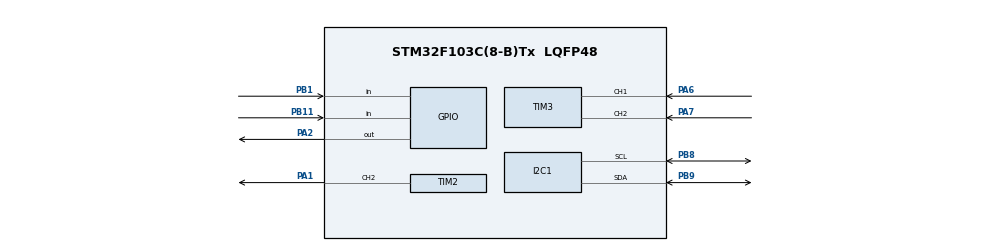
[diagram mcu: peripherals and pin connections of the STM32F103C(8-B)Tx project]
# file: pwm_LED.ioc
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Mcu.Family=STM32F1
Mcu.Name=STM32F103C(8-B)Tx
Mcu.Package=LQFP48
NVIC.PriorityGroup=NVIC_PRIORITYGROUP_4
PA1.Signal=S_TIM2_CH2
PA13.Mode=Serial_Wire
PA13.Signal=SYS_JTMS-SWDIO
PA14.Mode=Serial_Wire
PA14.Signal=SYS_JTCK-SWCLK
PA2.Signal=GPIO_Output
PA6.Signal=S_TIM3_CH1
PA7.Signal=S_TIM3_CH2
PB1.GPIO_PuPd=GPIO_PULLUP
PB1.Signal=GPIO_Input
PB11.GPIO_PuPd=GPIO_PULLUP
PB11.Signal=GPIO_Input
PB8.Mode=I2C
PB8.Signal=I2C1_SCL
PB9.Mode=I2C
PB9.Signal=I2C1_SDA
ProjectManager.HeapSize=0x200
ProjectManager.StackSize=0x400
ProjectManager.TargetToolchain=CMake
RCC.APB1Freq_Value=8000000
RCC.APB2Freq_Value=8000000
SH.S_TIM2_CH2.0=TIM2_CH2,PWM Generation2 CH2
SH.S_TIM3_CH1.0=TIM3_CH1,Encoder_Interface
SH.S_TIM3_CH2.0=TIM3_CH2,Encoder_Interface
TIM2.Channel-PWM\ Generation2\ CH2=TIM_CHANNEL_2
board=custom

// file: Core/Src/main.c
/* USER CODE BEGIN Header */
/**
  ******************************************************************************
  * @file           : main.c
  * @brief          : Main program body
  ******************************************************************************
  * @attention
  *
  * Copyright (c) 2026 STMicroelectronics.
  * All rights reserved.
  *
  * This software is licensed under terms that can be found in the LICENSE file
  * in the root directory of this software component.
  * If no LICENSE file comes with this software, it is provided AS-IS.
  *
  ******************************************************************************
  */
/* USER CODE END Header */
#include "main.h"

I2C_HandleTypeDef hi2c1;

TIM_HandleTypeDef htim2;
TIM_HandleTypeDef htim3;

/* USER CODE BEGIN PV */
static uint16_t s_bright   = 500u;   /* 上电半亮 */
static uint16_t s_enc_last = 0u;
static int32_t s_enc_acc = 0;   /* 攒够一格才动作 */

/* USER CODE END PV */

void SystemClock_Config(void);
static void MX_GPIO_Init(void);
static void MX_I2C1_Init(void);
static void MX_TIM2_Init(void);
static void MX_TIM3_Init(void);

int main(void)
{

  /* MCU Configuration--------------------------------------------------------*/

  /* Reset of all peripherals, Initializes the Flash interface and the Systick. */
  HAL_Init();

  /* Configure the system clock */
  SystemClock_Config();

  /* Initialize all configured peripherals */
  MX_GPIO_Init();
  MX_I2C1_Init();
  MX_TIM2_Init();
  MX_TIM3_Init();
  /* USER CODE BEGIN 2 */
/* 启动 TIM3 硬件编码器接口（A = PA6, B = PA7, C 接 GND）*/
  HAL_TIM_Encoder_Start(&htim3, TIM_CHANNEL_ALL);
  s_enc_last = (uint16_t)__HAL_TIM_GET_COUNTER(&htim3);

  /* 启动 TIM2_CH2 的 PWM 输出（LED = PA1）*/
  HAL_TIM_PWM_Start(&htim2, TIM_CHANNEL_2);
  __HAL_TIM_SET_COMPARE(&htim2, TIM_CHANNEL_2, s_bright);

  /* USER CODE END 2 */

  /* Infinite loop */
  while (1)
  {
        /* ---- 编码器：硬件已算好方向和计数，读增量即可 ---- */
        uint16_t now   = (uint16_t)__HAL_TIM_GET_COUNTER(&htim3);
    int16_t  delta = (int16_t)(now - s_enc_last);
    s_enc_last = now;

    s_enc_acc += delta;                                    /* 先攒起来，不急着动作 */

    uint8_t changed = 0;

    /* 顺时针：每攒够一格就加一档 */
    while (s_enc_acc >= (int32_t)ENC_COUNTS_PER_DETENT)
    {
      s_enc_acc -= (int32_t)ENC_COUNTS_PER_DETENT;
      s_bright = (s_bright + BRIGHT_STEP <= BRIGHT_MAX)
                 ? (uint16_t)(s_bright + BRIGHT_STEP) : BRIGHT_MAX;
      changed = 1;
    }

    /* 逆时针：每攒够一格就减一档 */
    while (s_enc_acc <= -(int32_t)ENC_COUNTS_PER_DETENT)
    {
      s_enc_acc += (int32_t)ENC_COUNTS_PER_DETENT;
      s_bright = (s_bright >= BRIGHT_STEP) ? (uint16_t)(s_bright - BRIGHT_STEP) : 0u;
      changed = 1;
    }

    if (changed)
    {
      __HAL_TIM_SET_COMPARE(&htim2, TIM_CHANNEL_2, s_bright);
    }

  }
}

void SystemClock_Config(void)
{
  RCC_OscInitTypeDef RCC_OscInitStruct = {0};
  RCC_ClkInitTypeDef RCC_ClkInitStruct = {0};

  /** Initializes the RCC Oscillators according to the specified parameters
  * in the RCC_OscInitTypeDef structure.
  */
  RCC_OscInitStruct.OscillatorType = RCC_OSCILLATORTYPE_HSI;
  RCC_OscInitStruct.HSIState = RCC_HSI_ON;
  RCC_OscInitStruct.HSICalibrationValue = RCC_HSICALIBRATION_DEFAULT;
  RCC_OscInitStruct.PLL.PLLState = RCC_PLL_NONE;
  if (HAL_RCC_OscConfig(&RCC_OscInitStruct) != HAL_OK)
  {
    Error_Handler();
  }

  /** Initializes the CPU, AHB and APB buses clocks
  */
  RCC_ClkInitStruct.ClockType = RCC_CLOCKTYPE_HCLK|RCC_CLOCKTYPE_SYSCLK
                              |RCC_CLOCKTYPE_PCLK1|RCC_CLOCKTYPE_PCLK2;
  RCC_ClkInitStruct.SYSCLKSource = RCC_SYSCLKSOURCE_HSI;
  RCC_ClkInitStruct.AHBCLKDivider = RCC_SYSCLK_DIV1;
  RCC_ClkInitStruct.APB1CLKDivider = RCC_HCLK_DIV1;
  RCC_ClkInitStruct.APB2CLKDivider = RCC_HCLK_DIV1;

  if (HAL_RCC_ClockConfig(&RCC_ClkInitStruct, FLASH_LATENCY_0) != HAL_OK)
  {
    Error_Handler();
  }
}

static void MX_I2C1_Init(void)
{

  hi2c1.Instance = I2C1;
  hi2c1.Init.ClockSpeed = 100000;
  hi2c1.Init.DutyCycle = I2C_DUTYCYCLE_2;
  hi2c1.Init.OwnAddress1 = 0;
  hi2c1.Init.AddressingMode = I2C_ADDRESSINGMODE_7BIT;
  hi2c1.Init.DualAddressMode = I2C_DUALADDRESS_DISABLE;
  hi2c1.Init.OwnAddress2 = 0;
  hi2c1.Init.GeneralCallMode = I2C_GENERALCALL_DISABLE;
  hi2c1.Init.NoStretchMode = I2C_NOSTRETCH_DISABLE;
  if (HAL_I2C_Init(&hi2c1) != HAL_OK)
  {
    Error_Handler();
  }

}

static void MX_TIM2_Init(void)
{

  TIM_MasterConfigTypeDef sMasterConfig = {0};
  TIM_OC_InitTypeDef sConfigOC = {0};

  htim2.Instance = TIM2;
  htim2.Init.Prescaler = 7;
  htim2.Init.CounterMode = TIM_COUNTERMODE_UP;
  htim2.Init.Period = 999;
  htim2.Init.ClockDivision = TIM_CLOCKDIVISION_DIV1;
  htim2.Init.AutoReloadPreload = TIM_AUTORELOAD_PRELOAD_DISABLE;
  if (HAL_TIM_PWM_Init(&htim2) != HAL_OK)
  {
    Error_Handler();
  }
  sMasterConfig.MasterOutputTrigger = TIM_TRGO_RESET;
  sMasterConfig.MasterSlaveMode = TIM_MASTERSLAVEMODE_DISABLE;
  if (HAL_TIMEx_MasterConfigSynchronization(&htim2, &sMasterConfig) != HAL_OK)
  {
    Error_Handler();
  }
  sConfigOC.OCMode = TIM_OCMODE_PWM1;
  sConfigOC.Pulse = 0;
  sConfigOC.OCPolarity = TIM_OCPOLARITY_HIGH;
  sConfigOC.OCFastMode = TIM_OCFAST_DISABLE;
  if (HAL_TIM_PWM_ConfigChannel(&htim2, &sConfigOC, TIM_CHANNEL_2) != HAL_OK)
  {
    Error_Handler();
  }
  HAL_TIM_MspPostInit(&htim2);

}

static void MX_TIM3_Init(void)
{

  TIM_Encoder_InitTypeDef sConfig = {0};
  TIM_MasterConfigTypeDef sMasterConfig = {0};

  htim3.Instance = TIM3;
  htim3.Init.Prescaler = 0;
  htim3.Init.CounterMode = TIM_COUNTERMODE_UP;
  htim3.Init.Period = 65535;
  htim3.Init.ClockDivision = TIM_CLOCKDIVISION_DIV1;
  htim3.Init.AutoReloadPreload = TIM_AUTORELOAD_PRELOAD_DISABLE;
  sConfig.EncoderMode = TIM_ENCODERMODE_TI1;
  sConfig.IC1Polarity = TIM_ICPOLARITY_RISING;
  sConfig.IC1Selection = TIM_ICSELECTION_DIRECTTI;
  sConfig.IC1Prescaler = TIM_ICPSC_DIV1;
  sConfig.IC1Filter = 10;
  sConfig.IC2Polarity = TIM_ICPOLARITY_RISING;
  sConfig.IC2Selection = TIM_ICSELECTION_DIRECTTI;
  sConfig.IC2Prescaler = TIM_ICPSC_DIV1;
  sConfig.IC2Filter = 10;
  if (HAL_TIM_Encoder_Init(&htim3, &sConfig) != HAL_OK)
  {
    Error_Handler();
  }
  sMasterConfig.MasterOutputTrigger = TIM_TRGO_RESET;
  sMasterConfig.MasterSlaveMode = TIM_MASTERSLAVEMODE_DISABLE;
  if (HAL_TIMEx_MasterConfigSynchronization(&htim3, &sMasterConfig) != HAL_OK)
  {
    Error_Handler();
  }

}

static void MX_GPIO_Init(void)
{
  GPIO_InitTypeDef GPIO_InitStruct = {0};

  /* GPIO Ports Clock Enable */
  __HAL_RCC_GPIOA_CLK_ENABLE();
  __HAL_RCC_GPIOB_CLK_ENABLE();

  /*Configure GPIO pin Output Level */
  HAL_GPIO_WritePin(GPIOA, GPIO_PIN_2, GPIO_PIN_RESET);

  /*Configure GPIO pin : PA2 */
  GPIO_InitStruct.Pin = GPIO_PIN_2;
  GPIO_InitStruct.Mode = GPIO_MODE_OUTPUT_PP;
  GPIO_InitStruct.Pull = GPIO_NOPULL;
  GPIO_InitStruct.Speed = GPIO_SPEED_FREQ_LOW;
  HAL_GPIO_Init(GPIOA, &GPIO_InitStruct);

  /*Configure GPIO pins : PB1 PB11 */
  GPIO_InitStruct.Pin = GPIO_PIN_1|GPIO_PIN_11;
  GPIO_InitStruct.Mode = GPIO_MODE_INPUT;
  GPIO_InitStruct.Pull = GPIO_PULLUP;
  HAL_GPIO_Init(GPIOB, &GPIO_InitStruct);

}

void Error_Handler(void)
{
  __disable_irq();
  while (1)
  {
  }
}
